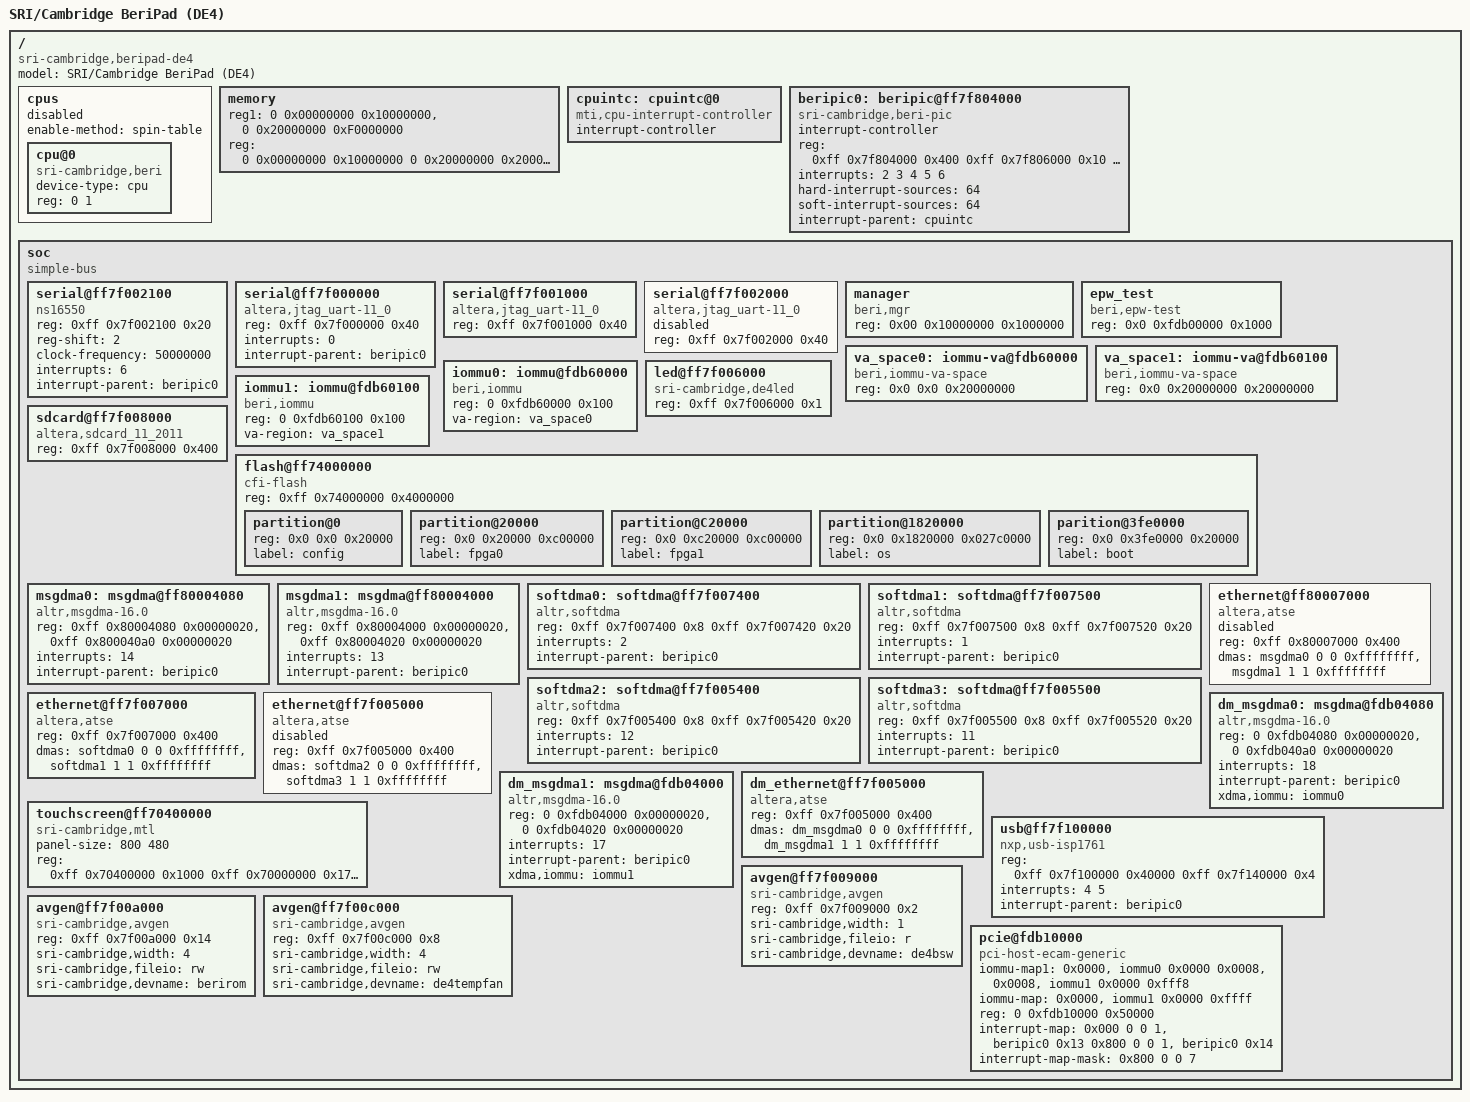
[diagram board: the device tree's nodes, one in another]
/*-
 * Copyright (c) 2012-2013 Robert N. M. Watson
 * Copyright (c) 2013 SRI International
 * All rights reserved.
 *
 * This software was developed by SRI International and the University of
 * Cambridge Computer Laboratory under DARPA/AFRL contract (FA8750-10-C-0237)
 * ("CTSRD"), as part of the DARPA CRASH research programme.
 *
 * Redistribution and use in source and binary forms, with or without
 * modification, are permitted provided that the following conditions
 * are met:
 * 1. Redistributions of source code must retain the above copyright
 *    notice, this list of conditions and the following disclaimer.
 * 2. Redistributions in binary form must reproduce the above copyright
 *    notice, this list of conditions and the following disclaimer in the
 *    documentation and/or other materials provided with the distribution.
 *
 * THIS SOFTWARE IS PROVIDED BY THE AUTHOR AND CONTRIBUTORS ``AS IS'' AND
 * ANY EXPRESS OR IMPLIED WARRANTIES, INCLUDING, BUT NOT LIMITED TO, THE
 * IMPLIED WARRANTIES OF MERCHANTABILITY AND FITNESS FOR A PARTICULAR PURPOSE
 * ARE DISCLAIMED.  IN NO EVENT SHALL THE AUTHOR OR CONTRIBUTORS BE LIABLE
 * FOR ANY DIRECT, INDIRECT, INCIDENTAL, SPECIAL, EXEMPLARY, OR CONSEQUENTIAL
 * DAMAGES (INCLUDING, BUT NOT LIMITED TO, PROCUREMENT OF SUBSTITUTE GOODS
 * OR SERVICES; LOSS OF USE, DATA, OR PROFITS; OR BUSINESS INTERRUPTION)
 * HOWEVER CAUSED AND ON ANY THEORY OF LIABILITY, WHETHER IN CONTRACT, STRICT
 * LIABILITY, OR TORT (INCLUDING NEGLIGENCE OR OTHERWISE) ARISING IN ANY WAY
 * OUT OF THE USE OF THIS SOFTWARE, EVEN IF ADVISED OF THE POSSIBILITY OF
 * SUCH DAMAGE.
 *
 * $FreeBSD$
 */

/dts-v1/;

/*
 * Device names here have been largely made up on the spot, especially for the
 * "compatible" strings, and might want to be revised.
 *
 * For now, use 32-bit addressing as our Avalon bus is 32-bit.  However, in
 * the future, we should likely change to 64-bit.
 */

/ {
	model = "SRI/Cambridge BeriPad (DE4)";
	compatible = "sri-cambridge,beripad-de4";
	#address-cells = <2>;
	#size-cells = <1>;

	cpus {
		#address-cells = <1>;
		#size-cells = <1>;

		/*
		 * Secondary CPUs all start disabled and use the
		 * spin-table enable method.  cpu-release-addr must be
		 * specified for each cpu other than cpu@0.  Values of
		 * cpu-release-addr grow down from 0x100000 (kernel).
		 */
		status = "disabled";
		enable-method = "spin-table";

		cpu@0 {
			device-type = "cpu";
			compatible = "sri-cambridge,beri";

			reg = <0 1>;
			status = "okay";
		};

/*
		cpu@1 {
			device-type = "cpu";
			compatible = "sri-cambridge,beri";

			reg = <1 1>;
			// XXX: should we need cached prefix?
			cpu-release-addr = <0xffffffff 0x800fffe0>;
		};
*/
	};

	memory {
		device_type = "memory";
		/*
		 * Memory is reserved for device-model,
		 * see beri,mgr device below.
		 * 0x10000000 - 0x20000000 reserved for device model
		 */
		reg1 = <0 0x00000000 0x10000000>,	// 256M at 0x0
		       <0 0x20000000 0xF0000000>;	// 768M-256M at 0x20000000

		reg = <	0 0x00000000 0x10000000
			0 0x20000000 0x20000000 >;
	};

	cpuintc: cpuintc@0 {
		#address-cells = <0>;
		#interrupt-cells = <1>;
		interrupt-controller;
		compatible = "mti,cpu-interrupt-controller";
	};

	beripic0: beripic@ff7f804000 {
		compatible = "sri-cambridge,beri-pic";
		interrupt-controller;
		#address-cells = <0>;
		#interrupt-cells = <1>;
		reg = <0xff 0x7f804000 0x400
		       0xff 0x7f806000 0x10
		       0xff 0x7f806080 0x10
		       0xff 0x7f806100 0x10>;
		interrupts = < 2 3 4 5 6 >;
		hard-interrupt-sources = <64>;
		soft-interrupt-sources = <64>;
		interrupt-parent = <&cpuintc>;
	};

/*
	beripic1: beripic@ff7f808000 {
		compatible = "sri-cambridge,beri-pic";
		interrupt-controller;
		#address-cells = <0>;
		#interrupt-cells = <1>;
		reg = <0xff 0x7f808000 0x400
		       0xff 0x7f80a000 0x10
		       0xff 0x7f80a080 0x10
		       0xff 0x7f80a100 0x10>;
		interrupts = < 2 3 4 5 6 >;
		hard-interrupt-sources = <64>;
		soft-interrupt-sources = <64>;
		interrupt-parent = <&cpuintc>;
	};
*/

	soc {
		#address-cells = <2>;
		#size-cells = <1>;
		#interrupt-cells = <1>;

		compatible = "simple-bus", "mips,mips4k";
		ranges;

		serial@ff7f002100 {
			compatible = "ns16550";
			reg = <0xff 0x7f002100 0x20>;
			reg-shift = <2>;
			clock-frequency = <50000000>;
			interrupts = <6>;
			interrupt-parent = <&beripic0>;
		};

		serial@ff7f000000 {
			compatible = "altera,jtag_uart-11_0";
			reg = <0xff 0x7f000000 0x40>;
			interrupts = <0>;
			interrupt-parent = <&beripic0>;
		};

		serial@ff7f001000 {
			compatible = "altera,jtag_uart-11_0";
			reg = <0xff 0x7f001000 0x40>;
			status = "okay";
		};

		serial@ff7f002000 {
			compatible = "altera,jtag_uart-11_0";
			reg = <0xff 0x7f002000 0x40>;
			status = "disabled";
		};

		manager {
			compatible = "beri,mgr";
			reg = <0x00 0x10000000 0x1000000>;	/* 16MB */
			status = "okay";
		};

		epw_test {
			compatible = "beri,epw-test";
			reg = <0x0 0xfdb00000 0x1000>;
			status = "okay";
		};

		va_space0: iommu-va@fdb60000 {
			compatible = "beri,iommu-va-space";
			reg = <0x0 0x0 0x20000000>;
			status = "okay";
		};

		va_space1: iommu-va@fdb60100 {
			compatible = "beri,iommu-va-space";
			reg = <0x0 0x20000000 0x20000000>;
			status = "okay";
		};

		iommu0: iommu@fdb60000 {
			compatible = "beri,iommu";
			reg = <0 0xfdb60000 0x100>;
			va-region = <&va_space0>;
			status = "okay";
		};

		iommu1: iommu@fdb60100 {
			compatible = "beri,iommu";
			reg = <0 0xfdb60100 0x100>;
			va-region = <&va_space1>;
			status = "okay";
		};

		sdcard@ff7f008000 {
			compatible = "altera,sdcard_11_2011";
			reg = <0xff 0x7f008000 0x400>;
		};

		led@ff7f006000 {
			compatible = "sri-cambridge,de4led";
			reg = <0xff 0x7f006000 0x1>;
		};

		/*
		 * XXX-BZ keep flash before ethernet so that atse can read the
		 * Ethernet addresses for now.
		 */
		flash@ff74000000 {
			#address-cells = <2>;
			#size-cells = <1>;
			compatible = "cfi-flash";
			reg = <0xff 0x74000000 0x4000000>;

			/* Board configuration */
			partition@0 {
				reg = <0x0 0x0 0x20000>;
				label = "config";
			};

			/* Power up FPGA image */
			partition@20000 {
				reg = <0x0 0x20000 0xc00000>;
				label = "fpga0";
			};

			/* Secondary FPGA image (on RE_CONFIGn button) */
			partition@C20000 {
				reg = <0x0 0xc20000 0xc00000>;
				label = "fpga1";
			};

			/* Space for operating system use */
			partition@1820000 {
				reg = <0x0 0x1820000 0x027c0000>;
				label = "os";
			};

			/* Second stage bootloader */
			parition@3fe0000 {
				reg = <0x0 0x3fe0000 0x20000>;
				label = "boot";
			};
		};

		msgdma0: msgdma@ff80004080 { 
			compatible = "altr,msgdma-16.0", "altr,msgdma-1.0"; 
			reg = <0xff 0x80004080 0x00000020>,
			      <0xff 0x800040a0 0x00000020>; 
			reg-names = "csr", "descriptor_slave"; 
			interrupts = <14>;
			interrupt-parent = <&beripic0>;
			#dma-cells = <3>;
		};

		msgdma1: msgdma@ff80004000 { 
			compatible = "altr,msgdma-16.0", "altr,msgdma-1.0"; 
			reg = <0xff 0x80004000 0x00000020>,
			      <0xff 0x80004020 0x00000020>; 
			reg-names = "csr", "descriptor_slave"; 
			interrupts = <13>;
			interrupt-parent = <&beripic0>;
			#dma-cells = <3>;
		};

		softdma0: softdma@ff7f007400 {
			compatible = "altr,softdma";
			reg = < 0xff 0x7f007400 0x8		/* tx */
				0xff 0x7f007420 0x20 >;	/* txc */
			interrupts = <2>;
			interrupt-parent = <&beripic0>;
			#dma-cells = <3>;
		};

		softdma1: softdma@ff7f007500 {
			compatible = "altr,softdma";
			reg = < 0xff 0x7f007500 0x8		/* rx */
				0xff 0x7f007520 0x20 >;	/* rxc */
			interrupts = <1>;
			interrupt-parent = <&beripic0>;
			#dma-cells = <3>;
		};

		softdma2: softdma@ff7f005400 {
			compatible = "altr,softdma";
			reg = < 0xff 0x7f005400 0x8		/* tx */
				0xff 0x7f005420 0x20 >;	/* txc */
			interrupts = <12>;
			interrupt-parent = <&beripic0>;
			#dma-cells = <3>;
		};

		softdma3: softdma@ff7f005500 {
			compatible = "altr,softdma";
			reg = < 0xff 0x7f005500 0x8		/* rx */
				0xff 0x7f005520 0x20 >;	/* rxc */
			interrupts = <11>;
			interrupt-parent = <&beripic0>;
			#dma-cells = <3>;
		};

		ethernet@ff80007000 {
			compatible = "altera,atse";
			reg = <0xff 0x80007000 0x400>;		/* mac */
			dmas = <&msgdma0 0 0 0xffffffff>,
			       <&msgdma1 1 1 0xffffffff>;
			dma-names = "tx", "rx";
			status = "disabled";
		};

		ethernet@ff7f007000 {
			compatible = "altera,atse";
			reg = <0xff 0x7f007000 0x400>;		/* mac */
			dmas = <&softdma0 0 0 0xffffffff>,
			       <&softdma1 1 1 0xffffffff>;
			dma-names = "tx", "rx";
			status = "okay";
		};

		ethernet@ff7f005000 {
			compatible = "altera,atse";
			reg = <0xff 0x7f005000 0x400>;
			dmas = <&softdma2 0 0 0xffffffff>,
			       <&softdma3 1 1 0xffffffff>;
			dma-names = "tx", "rx";
			status = "disabled";
		};

		dm_msgdma0: msgdma@fdb04080 { 
			compatible = "altr,msgdma-16.0", "altr,msgdma-1.0"; 
			reg = <0 0xfdb04080 0x00000020>,
			      <0 0xfdb040a0 0x00000020>; 
			reg-names = "csr", "descriptor_slave"; 
			interrupts = <18>;
			interrupt-parent = <&beripic0>;
			#dma-cells = <3>;
			xdma,iommu = <&iommu0>;
		};

		dm_msgdma1: msgdma@fdb04000 { 
			compatible = "altr,msgdma-16.0", "altr,msgdma-1.0"; 
			reg = <0 0xfdb04000 0x00000020>,
			      <0 0xfdb04020 0x00000020>; 
			reg-names = "csr", "descriptor_slave"; 
			interrupts = <17>;
			interrupt-parent = <&beripic0>;
			#dma-cells = <3>;
			xdma,iommu = <&iommu1>;
		};

		dm_ethernet@ff7f005000 {
			compatible = "altera,atse";
			reg = <0xff 0x7f005000 0x400>;
			dmas = <&dm_msgdma0 0 0 0xffffffff>,
			       <&dm_msgdma1 1 1 0xffffffff>;
			dma-names = "tx", "rx";
			status = "okay";
		};

		touchscreen@ff70400000 {
			compatible = "sri-cambridge,mtl";
			panel-size = < 800 480 >;
			reg = <0xff 0x70400000 0x1000
			       0xff 0x70000000 0x177000
			       0xff 0x70177000 0x2000>;
		};

		usb@ff7f100000 {
			compatible = "nxp,usb-isp1761";
			reg = <0xff 0x7f100000 0x40000
			       0xff 0x7f140000 0x4>;
			// IRQ 4 is DC, IRQ 5 is HC.
			interrupts = <4 5>;
			interrupt-parent = <&beripic0>;
			//status = "disabled";
		};

		avgen@ff7f009000 {
			compatible = "sri-cambridge,avgen";
			reg = <0xff 0x7f009000 0x2>;	
			sri-cambridge,width = <1>;
			sri-cambridge,fileio = "r";
			sri-cambridge,devname = "de4bsw";
		};

		avgen@ff7f00a000 {
			compatible = "sri-cambridge,avgen";
			reg = <0xff 0x7f00a000 0x14>;
			sri-cambridge,width = <4>;
			sri-cambridge,fileio = "rw";
			sri-cambridge,devname = "berirom";
		};

		avgen@ff7f00c000 {
			compatible = "sri-cambridge,avgen";
			reg = <0xff 0x7f00c000 0x8>;
			sri-cambridge,width = <4>;
			sri-cambridge,fileio = "rw";
			sri-cambridge,devname = "de4tempfan";
		};

		pcie@fdb10000 {
			compatible = "pci-host-ecam-generic";
			device_type = "pci";
			#interrupt-cells = <1>;
			#address-cells = <3>;
			#size-cells = <2>;

			/*
			 * Devices within bus 0 slot 0 are mastered
			 * via iommu0, everything else with iommu1.
			 */
			iommu-map1 = <0x0000 &iommu0 0x0000 0x0008>,
				    <0x0008 &iommu1 0x0000 0xfff8>;
			iommu-map = <0x0000 &iommu1 0x0000 0xffff>;

			reg = <0 0xfdb10000 0x50000>;
			reg-names = "PCI ECAM";

			//attributes      pci_addr   cpu_addr         size
			ranges =
			  <0x02000000 0 0xfdb20000 0 0xfdb20000 0 0x00020000	//e1000 bar 0
			   0x01000000 0 0x00000010 0 0x00000010 0 0x00010000	//e1000 bar 2
			   0x43000000 0 0xfdb40000 0 0xfdb40000 0 0x00010000	//e1000 bar 1
			   0x02000000 0 0xfdb50000 0 0xfdb50000 0 0x00010000>;	//ahci-hd bar 0

			// PCI_DEVICE(3)  INT#(1)  CONTROLLER(PHANDLE)  CONTROLLER_DATA(1)

			interrupt-map = < 0x000 0 0  1  &beripic0  0x13 	//e1000
					  0x800 0 0  1  &beripic0  0x14 >; 	//ahci
			interrupt-map-mask = <0x800 0 0 7>;
		};
	};
};
